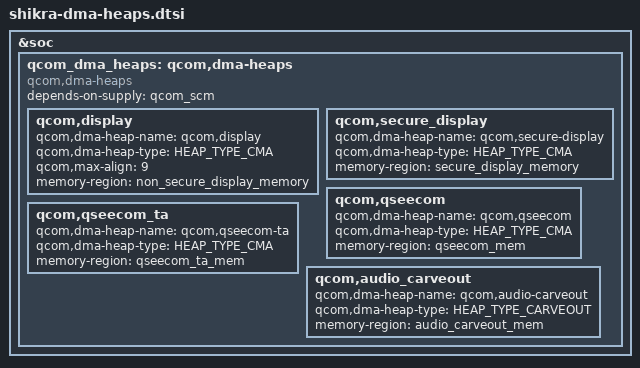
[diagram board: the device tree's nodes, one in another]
// SPDX-License-Identifier: BSD-3-Clause
/*
 * Copyright (c) Qualcomm Technologies, Inc. and/or its subsidiaries.
 */

#include <dt-bindings/arm/msm/qcom_dma_heap_dt_constants.h>

&soc {
	qcom_dma_heaps: qcom,dma-heaps {
		compatible = "qcom,dma-heaps";
		depends-on-supply = <&qcom_scm>;

		qcom,display {
			qcom,dma-heap-name = "qcom,display";
			qcom,dma-heap-type = <HEAP_TYPE_CMA>;
			qcom,max-align = <9>;
			memory-region = <&non_secure_display_memory>;
		};

		qcom,secure_display {
			qcom,dma-heap-name = "qcom,secure-display";
			qcom,dma-heap-type = <HEAP_TYPE_CMA>;
			memory-region = <&secure_display_memory>;
		};

		qcom,qseecom {
			qcom,dma-heap-name = "qcom,qseecom";
			qcom,dma-heap-type = <HEAP_TYPE_CMA>;
			memory-region = <&qseecom_mem>;
		};

		qcom,qseecom_ta {
			qcom,dma-heap-name = "qcom,qseecom-ta";
			qcom,dma-heap-type = <HEAP_TYPE_CMA>;
			memory-region = <&qseecom_ta_mem>;
		};

		qcom,audio_carveout {
			qcom,dma-heap-name = "qcom,audio-carveout";
			qcom,dma-heap-type = <HEAP_TYPE_CARVEOUT>;
			memory-region = <&audio_carveout_mem>;
		};
	};
};

